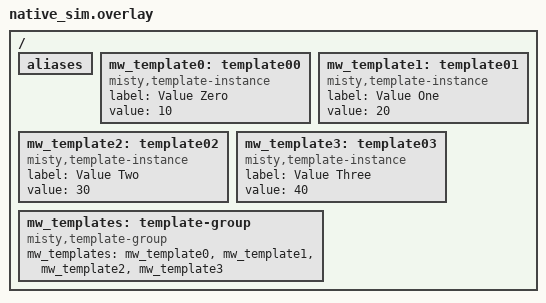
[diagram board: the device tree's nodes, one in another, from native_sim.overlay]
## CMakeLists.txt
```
cmake_minimum_required(VERSION 3.20.0)

find_package(Zephyr REQUIRED HINTS $ENV{ZEPHYR_BASE})
project(test_module)
zephyr_compile_definitions(PROJECT_NAME=${PROJECT_NAME})

# add location_module (the unit under test)
target_sources(app
    PRIVATE
    ../mainTemplate.c
	../drvr/src/msgqTemplate.c
	../drvr/src/wdtTemplate.c
	../drvr/src/template.c
	../drvr/src/zbusTemplate.c
	../../../common/zbusCommon.c
)

zephyr_include_directories(${ZEPHYR_BASE}/include/zephyr/)
zephyr_include_directories(${ZEPHYR_BASE}/subsys/testsuite/include)
target_include_directories(app PRIVATE ../drvr/inc)
target_include_directories(app PRIVATE ../../../common/inc)

target_link_options(app PRIVATE --whole-archive)

# add test file
target_sources(app PRIVATE src/testTemplate.c)
```

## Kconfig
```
##
# @file Kconfig
# @date 20250526
# @author flynnty
# @copyright flynnty 2025
#
# @brief
# Test Kconfig
#
#

menu "Zephyr"
source "Kconfig.zephyr"
endmenu

module = APP
module-str = APP
source "subsys/logging/Kconfig.template.log_config"



rsource "../Kconfig"

config APP_TEMPLATE_DRIVER
	bool "Use Real Time Clock Driver"
	default n
```

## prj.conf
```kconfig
#
# Copyright (c) 2022 Nordic Semiconductor ASA
#
# SPDX-License-Identifier: LicenseRef-Nordic-5-Clause
#
CONFIG_ZTEST=y

# Task Watchdog
CONFIG_TASK_WDT=y
CONFIG_TASK_WDT_CHANNELS=5
CONFIG_TASK_WDT_MIN_TIMEOUT=10000

# Configure Zbus
CONFIG_ZBUS=y
CONFIG_ZBUS_LOG_LEVEL_DBG=y
CONFIG_ZBUS_OBSERVER_NAME=y
CONFIG_ZBUS_RUNTIME_OBSERVERS=y


# Configure Logging
CONFIG_LOG=y
CONFIG_ASSERT=y
CONFIG_BOOT_BANNER=n

# Module Template Testing
CONFIG_APP_TEMPLATE_DRIVER=y
CONFIG_APP_TEMPLATE_LOG_LEVEL_DBG=y
```

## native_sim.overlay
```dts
/**
 * @file native_sim.overlay
 * @date 20250526
 * @author flynnty
 * @copyright flynnty 2025
 *
 * @brief
 * Sim Overlay
 *
 */

/ {
	aliases {
	};

	mw_template0: template00 {
		compatible = "misty,template-instance";
		#mw_template-cells = <0>;
		label = "Value Zero";
		value = <10>;
	};

	mw_template1: template01 {
		compatible = "misty,template-instance";
		#mw_template-cells = <0>;
		label = "Value One";
		value = <20>;
	};

	mw_template2: template02 {
		compatible = "misty,template-instance";
		#mw_template-cells = <0>;
		label = "Value Two";
		value = <30>;
	};

	mw_template3: template03 {
		compatible = "misty,template-instance";
		#mw_template-cells = <0>;
		label = "Value Three";
		value = <40>;
	};

	mw_templates: template-group {
		compatible = "misty,template-group";
		mw_templates = <&mw_template0 &mw_template1 &mw_template2 &mw_template3>;
	};
};
```

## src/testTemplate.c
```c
/**
 * @file testTemplate.c
 * @date 20250526
 * @author flynnty
 * @copyright flynnty 2025
 *
 * @brief
 * Module Unit Test to test driver header API and ZBUS interface to the Driver
 *
 */

/**** Includes ********************************************************************************************************/

#include "msgqTemplate.h"
#include "template.h"
#include "wdtTemplate.h"
#include "zbusCommon.h"
#include "zbusTemplate.h"
#include <zephyr/irq_offload.h>
#include <zephyr/kernel.h>
#include <zephyr/logging/log.h>
#include <zephyr/zbus/zbus.h>
#include <zephyr/ztest.h>

/**** Defines *********************************************************************************************************/

#define TEMPLATE_GROUP_NODE DT_NODELABEL( mw_templates )
#define TEMPLATE_CNT        DT_PROP_LEN( TEMPLATE_GROUP_NODE, mw_templates )
#define TEMPLATE_NODE( i )  DT_PHANDLE_BY_IDX( TEMPLATE_GROUP_NODE, mw_templates, i )

#define TEMPLATE_LABEL_GET( n, _ ) DT_PROP( TEMPLATE_NODE( n ), label ),
#define TEMPLATE_VALUE_GET( n, _ ) DT_PROP( TEMPLATE_NODE( n ), value ),

/**** Types ***********************************************************************************************************/
/**** Variables *******************************************************************************************************/
static uint32_t getVal;
static bool zbusCbFired = false;

// grab individual button settings from the overlay config
static const uint32_t templateValues[] = { LISTIFY( TEMPLATE_CNT, TEMPLATE_VALUE_GET, () ) };

/**** Prototypes ******************************************************************************************************/
static void *testSetup( void );
static void testTeardown( void * );
static void zbusListenerCb( const struct zbus_channel *chan );
static int zbusListenerCbWait();

/**** Macros **********************************************************************************************************/

LOG_MODULE_REGISTER( test_module, LOG_LEVEL_DBG );

ZBUS_LISTENER_DEFINE( template_test_lis, zbusListenerCb );
ZBUS_CHAN_ADD_OBS( ZBUS_CHAN_TEMPLATE_VAL_SUB, template_test_lis, 0 );

/**** Definitions *****************************************************************************************************/

static void *testSetup( void )
{
    // Give the template driver time to init
    k_sleep( K_MSEC( 1000 ) );

    return NULL;
}

static void testTeardown( void * )
{
    return;
}

void zbusListenerCb( const struct zbus_channel *chan )
{
    ZbusMsgContainer zbus = { 0 };

    if( chan == &ZBUS_CHAN_TEMPLATE_VAL_SUB ) {
        zbus.msg.template = *(ZbusMsgTemplate *)zbus_chan_const_msg( chan );
        getVal = zbus.msg.template.val;
    }
    zbusCbFired = true;
}

int zbusListenerCbWait()
{
    int16_t timeout = 1000;

    while( !zbusCbFired && timeout ) {
        k_sleep( K_MSEC( 1 ) );
        if( --timeout <= 0 ) {
            return 1;
        }
    }
    zbusCbFired = false;
    return 0;
}

ZTEST( test_template, test_template_hdr_init_val )
{
    templateInit();

    for( int i = 0; i < TEMPLATE_CNT; i++ ) {
        templateValRead( i, &getVal );
        zassert_equal( getVal, templateValues[i], "Test hrd init val [ set:%d | get:%d ]", templateValues[i], getVal );
    }
}

ZTEST( test_template, test_template_hdr_read_write_val )
{
    for( int i = 0; i < TEMPLATE_CNT; i++ ) {
        for( uint16_t setVal = 0; setVal < UINT16_MAX; setVal++ ) {
            templateValWrite( i, setVal );
            templateValRead( i, &getVal );
            zassert_equal( getVal, setVal, "Test hrd write/read val [ set:%d | get:%d ]", setVal, getVal );
        }
    }
}

ZTEST( test_template, test_template_zbus_init_val )
{
    templateInit();

    for( int i = 0; i < TEMPLATE_CNT; i++ ) {
        ZbusMsgTemplate zbusMsg = { 0 };
        zbusMsg.type = i;

        zbus_chan_pub( &ZBUS_CHAN_TEMPLATE_VAL_PUB_REQ, &zbusMsg, K_NO_WAIT );
        zbusListenerCbWait();

        zassert_equal( getVal, templateValues[i], "Test hrd init val [ set:%d | get:%d ]", templateValues[i], getVal );
    }
}

ZTEST( test_template, test_template_zbus_read_write_val )
{
    ZbusMsgTemplate zbusMsg = { 0 };
    for( int i = 0; i < TEMPLATE_CNT; i++ ) {
        for( uint8_t setVal = 0; setVal < UINT8_MAX; setVal++ ) {
            uint8_t setVal = i;
            zbusMsg.val = setVal;
            zbus_chan_pub( &ZBUS_CHAN_TEMPLATE_VAL_SET, &zbusMsg, K_NO_WAIT );
            zbus_chan_pub( &ZBUS_CHAN_TEMPLATE_VAL_PUB_REQ, &zbusMsg, K_NO_WAIT );
            zbusListenerCbWait();
            zassert_equal( getVal, setVal, "Test zbus write/read val [ set:%d | get:%d ]", setVal, getVal );
        }
    }
}

ZTEST_SUITE( test_template, NULL, testSetup, NULL, testTeardown, NULL );
```
